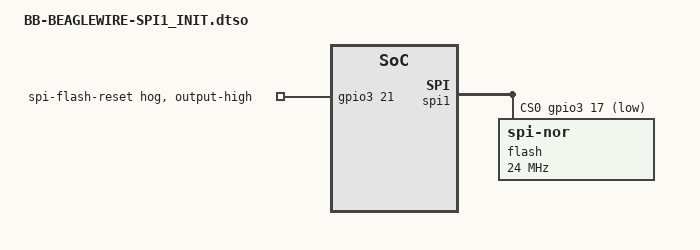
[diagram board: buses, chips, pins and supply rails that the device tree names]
// SPDX-License-Identifier: GPL-2.0-only
/dts-v1/;
/plugin/;

#include <dt-bindings/gpio/gpio.h>

/ {
    compatible = "ti,beaglebone", "ti,beaglebone-black";

    /* ---------- Pinmux ---------- */
    fragment@0 {
        target = <&am33xx_pinmux>;
        __overlay__ {

            spi1_pins: pinmux_spi1_pins {
                pinctrl-single,pins = <
                    0x190 0x33  /* P9_31 mcasp0_aclkx  SPI1_SCLK */
                    0x194 0x33  /* P9_29 mcasp0_fsx    SPI1_MISO */
                    0x198 0x33  /* P9_30 mcasp0_axr0   SPI1_MOSI */
                    0x19c 0x13  /* P9_28 mcasp0_ahclkr SPI1_CS0  */
                >;
            };

            p9_25_gpio: pinmux_p9_25_gpio {
                pinctrl-single,pins = <
                    0x1ac 0x07  /* P9_25 mcasp0_ahclkx GPIO output */
                >;
            };
        };
    };

    /* ---------- SPI1 controller ---------- */
    fragment@1 {
        target = <&spi1>;
        __overlay__ {
            #address-cells = <1>;
            #size-cells = <0>;

            status = "okay";
            pinctrl-names = "default";
            pinctrl-0 = <&spi1_pins>;
            cs-gpios = <&gpio3 17 GPIO_ACTIVE_LOW>; /* P9_28 */

            flash@0 {
                compatible = "jedec,spi-nor";
                reg = <0>;
                spi-max-frequency = <24000000>;
            };
        };
    };
    fragment@2 {
        target = <&gpio3>;
        __overlay__ {
            flash_reset {
                gpio-hog;
                gpios = <21 GPIO_ACTIVE_HIGH>;
                output-high;
                line-name = "spi-flash-reset";

                pinctrl-names = "default";
                pinctrl-0 = <&p9_25_gpio>;
            };
        };
    };
};
